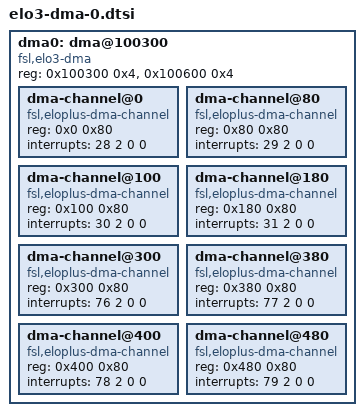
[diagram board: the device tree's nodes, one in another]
// SPDX-License-Identifier: GPL-2.0-or-later
/*
 * QorIQ Elo3 DMA device tree stub [ controller @ offset 0x100000 ]
 *
 * Copyright 2013 Freescale Semiconductor Inc.
 */

dma0: dma@100300 {
	#address-cells = <1>;
	#size-cells = <1>;
	compatible = "fsl,elo3-dma";
	reg = <0x100300 0x4>,
	      <0x100600 0x4>;
	ranges = <0x0 0x100100 0x500>;
	dma-channel@0 {
		compatible = "fsl,eloplus-dma-channel";
		reg = <0x0 0x80>;
		interrupts = <28 2 0 0>;
	};
	dma-channel@80 {
		compatible = "fsl,eloplus-dma-channel";
		reg = <0x80 0x80>;
		interrupts = <29 2 0 0>;
	};
	dma-channel@100 {
		compatible = "fsl,eloplus-dma-channel";
		reg = <0x100 0x80>;
		interrupts = <30 2 0 0>;
	};
	dma-channel@180 {
		compatible = "fsl,eloplus-dma-channel";
		reg = <0x180 0x80>;
		interrupts = <31 2 0 0>;
	};
	dma-channel@300 {
		compatible = "fsl,eloplus-dma-channel";
		reg = <0x300 0x80>;
		interrupts = <76 2 0 0>;
	};
	dma-channel@380 {
		compatible = "fsl,eloplus-dma-channel";
		reg = <0x380 0x80>;
		interrupts = <77 2 0 0>;
	};
	dma-channel@400 {
		compatible = "fsl,eloplus-dma-channel";
		reg = <0x400 0x80>;
		interrupts = <78 2 0 0>;
	};
	dma-channel@480 {
		compatible = "fsl,eloplus-dma-channel";
		reg = <0x480 0x80>;
		interrupts = <79 2 0 0>;
	};
};
